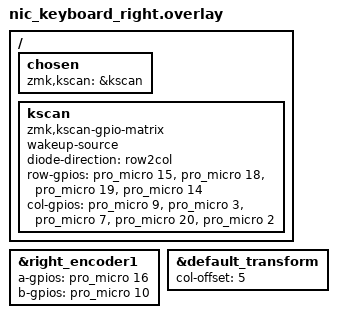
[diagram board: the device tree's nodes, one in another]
#include "nic_keyboard.dtsi"

/ {
    chosen {
        zmk,kscan = &kscan;
    };

    kscan: kscan {
        compatible = "zmk,kscan-gpio-matrix";
        wakeup-source;
        diode-direction = "row2col";

        row-gpios
            = <&pro_micro 15 GPIO_ACTIVE_HIGH>
            , <&pro_micro 18 GPIO_ACTIVE_HIGH>
            , <&pro_micro 19 GPIO_ACTIVE_HIGH>
            , <&pro_micro 14 GPIO_ACTIVE_HIGH>
            ;

        col-gpios
            = <&pro_micro 9  (GPIO_PULL_DOWN | GPIO_ACTIVE_HIGH)>
            , <&pro_micro 3  (GPIO_PULL_DOWN | GPIO_ACTIVE_HIGH)>
            , <&pro_micro 7  (GPIO_PULL_DOWN | GPIO_ACTIVE_HIGH)>
            , <&pro_micro 20 (GPIO_PULL_DOWN | GPIO_ACTIVE_HIGH)>
            , <&pro_micro 2  (GPIO_PULL_DOWN | GPIO_ACTIVE_HIGH)>
            ;
    };
};

&right_encoder1 {
    status = "okay";
    a-gpios = <&pro_micro 16 GPIO_PULL_UP>;
    b-gpios = <&pro_micro 10 GPIO_PULL_UP>;
};

&default_transform {
    col-offset = <5>;
};
